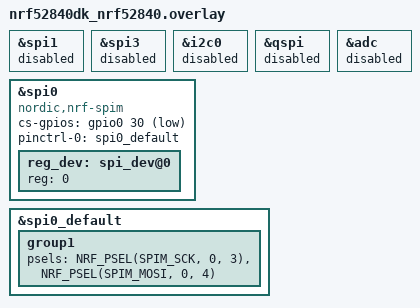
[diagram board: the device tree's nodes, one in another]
// To get started, press Ctrl+Space to bring up the completion menu and view the available nodes.

// You can also use the buttons in the sidebar to perform actions on nodes.
// Actions currently available include:

// * Enabling / disabling the node
// * Adding the bus to a bus
// * Removing the node
// * Connecting ADC channels

// For more help, browse the DeviceTree documentation at https://docs.zephyrproject.org/latest/guides/dts/index.html
// You can also visit the nRF DeviceTree extension documentation at https://nrfconnect.github.io/vscode-nrf-connect/devicetree/nrfdevicetree.html

&spi1 {
	status = "disabled";
};

&spi3 {
	status = "disabled";
};

&i2c0 {
	status = "disabled";
};

&qspi {
	status = "disabled";
};

&adc {
	status = "disabled";
};

&spi0 {
	compatible = "nordic,nrf-spim";
	status = "okay";
	cs-gpios = <&gpio0 30 GPIO_ACTIVE_LOW>;
	pinctrl-0 = < &spi0_default >;
	reg_dev:spi_dev@0 {
		reg = <0>;
	};
};

&spi0_default {
	group1 {
		psels = <NRF_PSEL(SPIM_SCK, 0, 3)>, <NRF_PSEL(SPIM_MOSI, 0, 4)>;
	};
};
